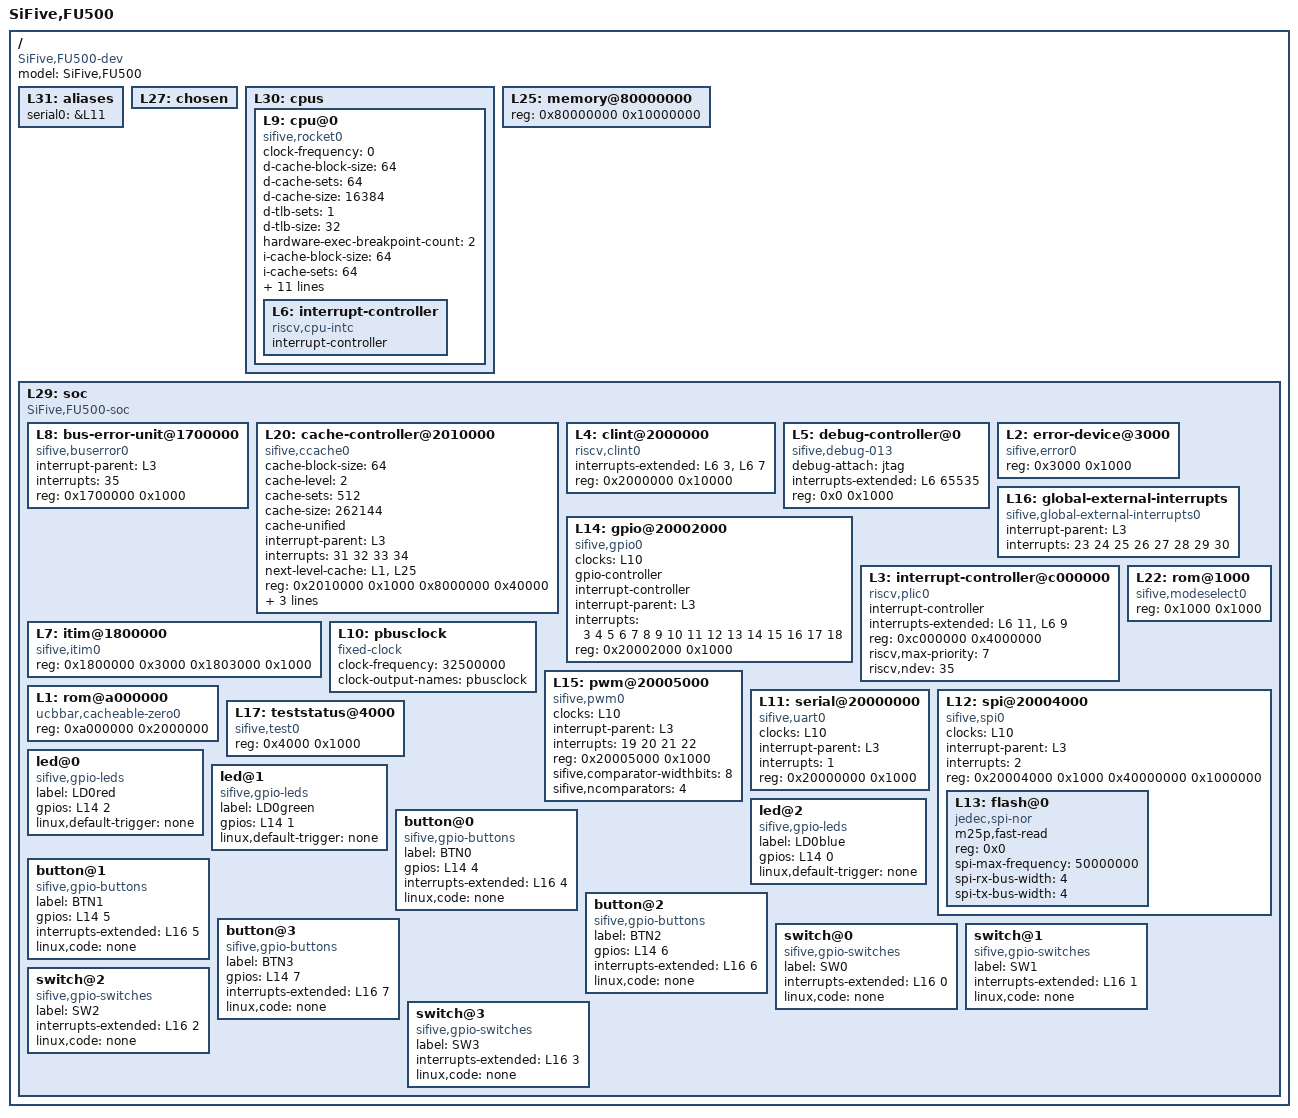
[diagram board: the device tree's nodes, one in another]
/dts-v1/;

/ {
	#address-cells = <1>;
	#size-cells = <1>;
	compatible = "SiFive,FU500-dev", "fu500-dev", "sifive-dev";
	model = "SiFive,FU500";
	L31: aliases {
		serial0 = &L11;
	};
	L27: chosen {
	};
	L30: cpus {
		#address-cells = <1>;
		#size-cells = <0>;
		L9: cpu@0 {
			clock-frequency = <0>;
			compatible = "sifive,rocket0", "riscv";
			d-cache-block-size = <64>;
			d-cache-sets = <64>;
			d-cache-size = <16384>;
			d-tlb-sets = <1>;
			d-tlb-size = <32>;
			device_type = "cpu";
			hardware-exec-breakpoint-count = <2>;
			i-cache-block-size = <64>;
			i-cache-sets = <64>;
			i-cache-size = <16384>;
			i-tlb-sets = <1>;
			i-tlb-size = <32>;
			mmu-type = "riscv,sv39";
			next-level-cache = <&L20>;
			reg = <0x0>;
			riscv,isa = "rv64imafdc";
			riscv,pmpregions = <8>;
			sifive,itim = <&L7>;
			status = "okay";
			timebase-frequency = <32500000>;
			tlb-split;
			L6: interrupt-controller {
				#interrupt-cells = <1>;
				compatible = "riscv,cpu-intc";
				interrupt-controller;
			};
		};
	};
	L25: memory@80000000 {
		device_type = "memory";
		reg = <0x80000000 0x10000000>;
	};
	L29: soc {
		#address-cells = <1>;
		#size-cells = <1>;
		compatible = "SiFive,FU500-soc", "fu500-soc", "sifive-soc", "simple-bus";
		ranges;
		L8: bus-error-unit@1700000 {
			compatible = "sifive,buserror0";
			interrupt-parent = <&L3>;
			interrupts = <35>;
			reg = <0x1700000 0x1000>;
			reg-names = "control";
		};
		L20: cache-controller@2010000 {
			cache-block-size = <64>;
			cache-level = <2>;
			cache-sets = <512>;
			cache-size = <262144>;
			cache-unified;
			compatible = "sifive,ccache0", "cache";
			interrupt-parent = <&L3>;
			interrupts = <31 32 33 34>;
			next-level-cache = <&L1 &L25>;
			reg = <0x2010000 0x1000 0x8000000 0x40000>;
			reg-names = "control", "sideband";
			sifive,a-mshr-count = <3>;
			sifive,bank-count = <1>;
			sifive,ecc-granularity = <8>;
		};
		L4: clint@2000000 {
			compatible = "riscv,clint0";
			interrupts-extended = <&L6 3 &L6 7>;
			reg = <0x2000000 0x10000>;
			reg-names = "control";
		};
		L5: debug-controller@0 {
			compatible = "sifive,debug-013", "riscv,debug-013";
			debug-attach = "jtag";
			interrupts-extended = <&L6 65535>;
			reg = <0x0 0x1000>;
			reg-names = "control";
		};
		L2: error-device@3000 {
			compatible = "sifive,error0";
			reg = <0x3000 0x1000>;
		};
		L16: global-external-interrupts {
			compatible = "sifive,global-external-interrupts0";
			interrupt-parent = <&L3>;
			interrupts = <23 24 25 26 27 28 29 30>;
		};
		L14: gpio@20002000 {
			#gpio-cells = <2>;
			#interrupt-cells = <2>;
			clocks = <&L10>;
			compatible = "sifive,gpio0", "sifive,gpio1";
			gpio-controller;
			interrupt-controller;
			interrupt-parent = <&L3>;
			interrupts = <3 4 5 6 7 8 9 10 11 12 13 14 15 16 17 18>;
			reg = <0x20002000 0x1000>;
			reg-names = "control";
		};
		L3: interrupt-controller@c000000 {
			#interrupt-cells = <1>;
			compatible = "riscv,plic0";
			interrupt-controller;
			interrupts-extended = <&L6 11 &L6 9>;
			reg = <0xc000000 0x4000000>;
			reg-names = "control";
			riscv,max-priority = <7>;
			riscv,ndev = <35>;
		};
		L7: itim@1800000 {
			compatible = "sifive,itim0";
			reg = <0x1800000 0x3000 0x1803000 0x1000>;
			reg-names = "mem", "control";
		};
		L10: pbusclock {
			#clock-cells = <0>;
			clock-frequency = <32500000>;
			clock-output-names = "pbusclock";
			compatible = "fixed-clock";
		};
		L15: pwm@20005000 {
			clocks = <&L10>;
			compatible = "sifive,pwm0";
			interrupt-parent = <&L3>;
			interrupts = <19 20 21 22>;
			reg = <0x20005000 0x1000>;
			reg-names = "control";
			sifive,comparator-widthbits = <8>;
			sifive,ncomparators = <4>;
		};
		L22: rom@1000 {
			compatible = "sifive,modeselect0";
			reg = <0x1000 0x1000>;
			reg-names = "mem";
		};
		L1: rom@a000000 {
			compatible = "ucbbar,cacheable-zero0";
			reg = <0xa000000 0x2000000>;
		};
		L11: serial@20000000 {
			clocks = <&L10>;
			compatible = "sifive,uart0";
			interrupt-parent = <&L3>;
			interrupts = <1>;
			reg = <0x20000000 0x1000>;
			reg-names = "control";
		};
		L12: spi@20004000 {
			#address-cells = <1>;
			#size-cells = <0>;
			clocks = <&L10>;
			compatible = "sifive,spi0";
			interrupt-parent = <&L3>;
			interrupts = <2>;
			reg = <0x20004000 0x1000 0x40000000 0x1000000>;
			reg-names = "control", "mem";
			L13: flash@0 {
				compatible = "jedec,spi-nor";
				m25p,fast-read;
				reg = <0x0>;
				spi-max-frequency = <50000000>;
				spi-rx-bus-width = <4>;
				spi-tx-bus-width = <4>;
			};
		};
		L17: teststatus@4000 {
			compatible = "sifive,test0";
			reg = <0x4000 0x1000>;
			reg-names = "control";
		};
				led@0 {
						compatible = "sifive,gpio-leds";
						label = "LD0red";
						gpios = <&L14 2>;
						linux,default-trigger = "none";
				};
				led@1 {
						compatible = "sifive,gpio-leds";
						label = "LD0green";
						gpios = <&L14 1>;
						linux,default-trigger = "none";
				};
				led@2 {
						compatible = "sifive,gpio-leds";
						label = "LD0blue";
						gpios = <&L14 0>;
						linux,default-trigger = "none";
				};
				button@0 {
						compatible = "sifive,gpio-buttons";
						label = "BTN0";
						gpios = <&L14 4>;
						interrupts-extended = <&L16 4>;
						linux,code = "none";
				};
				button@1 {
						compatible = "sifive,gpio-buttons";
						label = "BTN1";
						gpios = <&L14 5>;
						interrupts-extended = <&L16 5>;
						linux,code = "none";
				};
				button@2 {
						compatible = "sifive,gpio-buttons";
						label = "BTN2";
						gpios = <&L14 6>;
						interrupts-extended = <&L16 6>;
						linux,code = "none";
				};
				button@3 {
						compatible = "sifive,gpio-buttons";
						label = "BTN3";
						gpios = <&L14 7>;
						interrupts-extended = <&L16 7>;
						linux,code = "none";
				};
				switch@0 {
						compatible = "sifive,gpio-switches";
						label = "SW0";
						interrupts-extended = <&L16 0>;
						linux,code = "none";
				};
				switch@1 {
						compatible = "sifive,gpio-switches";
						label = "SW1";
						interrupts-extended = <&L16 1>;
						linux,code = "none";
				};
				switch@2 {
						compatible = "sifive,gpio-switches";
						label = "SW2";
						interrupts-extended = <&L16 2>;
						linux,code = "none";
				};
				switch@3 {
						compatible = "sifive,gpio-switches";
						label = "SW3";
						interrupts-extended = <&L16 3>;
						linux,code = "none";
				};

	};
};
